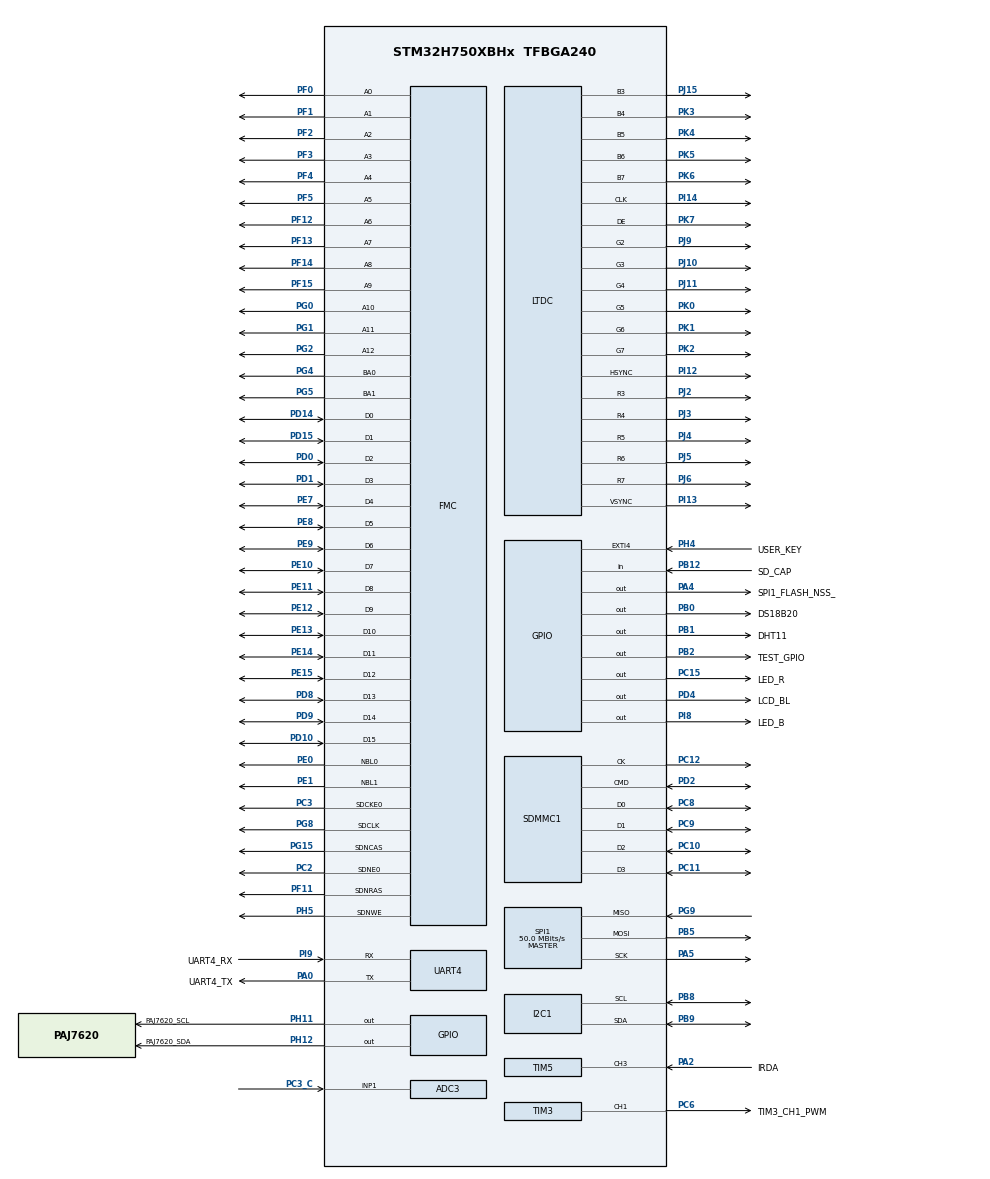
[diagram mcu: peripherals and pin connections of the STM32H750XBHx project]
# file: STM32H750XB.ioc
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ADC3.Channel-0\#ChannelRegularConversion=ADC_CHANNEL_1
ADC3.Channel-1\#ChannelRegularConversion=ADC_CHANNEL_VREFINT
ADC3.Channel-2\#ChannelRegularConversion=ADC_CHANNEL_TEMPSENSOR
ADC3.ClockPrescalerADC3=ADC_CLOCK_ASYNC_DIV2
ADC3.ContinuousConvMode=DISABLE
ADC3.DiscontinuousConvMode=ENABLE
ADC3.NbrOfConversion=3
ADC3.NbrOfConversionFlag=1
ADC3.NbrOfDiscConversion=1
ADC3.OffsetNumber-0\#ChannelRegularConversion=ADC_OFFSET_NONE
ADC3.OffsetNumber-1\#ChannelRegularConversion=ADC_OFFSET_NONE
ADC3.OffsetNumber-2\#ChannelRegularConversion=ADC_OFFSET_NONE
ADC3.OffsetSignedSaturation-0\#ChannelRegularConversion=DISABLE
ADC3.OffsetSignedSaturation-1\#ChannelRegularConversion=DISABLE
ADC3.OffsetSignedSaturation-2\#ChannelRegularConversion=DISABLE
ADC3.Rank-0\#ChannelRegularConversion=1
ADC3.Rank-1\#ChannelRegularConversion=2
ADC3.Rank-2\#ChannelRegularConversion=3
ADC3.SamplingTime-0\#ChannelRegularConversion=ADC_SAMPLETIME_387CYCLES_5
ADC3.SamplingTime-1\#ChannelRegularConversion=ADC_SAMPLETIME_387CYCLES_5
ADC3.SamplingTime-2\#ChannelRegularConversion=ADC_SAMPLETIME_387CYCLES_5
CORTEX_M7.BaseAddress-Cortex_Memory_Protection_Unit_Region0_Settings=0xc0000000
CORTEX_M7.CPU_DCache=Enabled
CORTEX_M7.CPU_ICache=Enabled
CORTEX_M7.Enable-Cortex_Memory_Protection_Unit_Region0_Settings=MPU_REGION_ENABLE
CORTEX_M7.IsBufferable-Cortex_Memory_Protection_Unit_Region0_Settings=MPU_ACCESS_BUFFERABLE
CORTEX_M7.IsCacheable-Cortex_Memory_Protection_Unit_Region0_Settings=MPU_ACCESS_CACHEABLE
CORTEX_M7.MPU_Control=MPU_PRIVILEGED_DEFAULT
CORTEX_M7.Size-Cortex_Memory_Protection_Unit_Region0_Settings=MPU_REGION_SIZE_32MB
CORTEX_M7.default_mode_Activation=0
DMA2D.ColorMode=DMA2D_OUTPUT_RGB888
Dma.Request0=UART4_RX
Dma.Request1=UART4_TX
Dma.UART4_RX.0.Direction=DMA_PERIPH_TO_MEMORY
Dma.UART4_RX.0.EventEnable=DISABLE
Dma.UART4_RX.0.FIFOMode=DMA_FIFOMODE_DISABLE
Dma.UART4_RX.0.Instance=DMA1_Stream2
Dma.UART4_RX.0.MemDataAlignment=DMA_MDATAALIGN_BYTE
Dma.UART4_RX.0.MemInc=DMA_MINC_ENABLE
Dma.UART4_RX.0.Mode=DMA_NORMAL
Dma.UART4_RX.0.PeriphDataAlignment=DMA_PDATAALIGN_BYTE
Dma.UART4_RX.0.PeriphInc=DMA_PINC_DISABLE
Dma.UART4_RX.0.Polarity=HAL_DMAMUX_REQ_GEN_RISING
Dma.UART4_RX.0.Priority=DMA_PRIORITY_MEDIUM
Dma.UART4_RX.0.RequestNumber=1
Dma.UART4_RX.0.SignalID=NONE
Dma.UART4_RX.0.SyncEnable=DISABLE
Dma.UART4_RX.0.SyncPolarity=HAL_DMAMUX_SYNC_NO_EVENT
Dma.UART4_RX.0.SyncRequestNumber=1
Dma.UART4_RX.0.SyncSignalID=NONE
Dma.UART4_TX.1.Direction=DMA_MEMORY_TO_PERIPH
Dma.UART4_TX.1.EventEnable=DISABLE
Dma.UART4_TX.1.FIFOMode=DMA_FIFOMODE_DISABLE
Dma.UART4_TX.1.Instance=DMA1_Stream4
Dma.UART4_TX.1.MemDataAlignment=DMA_MDATAALIGN_BYTE
Dma.UART4_TX.1.MemInc=DMA_MINC_ENABLE
Dma.UART4_TX.1.Mode=DMA_CIRCULAR
Dma.UART4_TX.1.PeriphDataAlignment=DMA_PDATAALIGN_BYTE
Dma.UART4_TX.1.PeriphInc=DMA_PINC_DISABLE
Dma.UART4_TX.1.Polarity=HAL_DMAMUX_REQ_GEN_RISING
Dma.UART4_TX.1.Priority=DMA_PRIORITY_MEDIUM
Dma.UART4_TX.1.RequestNumber=1
Dma.UART4_TX.1.SignalID=NONE
Dma.UART4_TX.1.SyncEnable=DISABLE
Dma.UART4_TX.1.SyncPolarity=HAL_DMAMUX_SYNC_NO_EVENT
Dma.UART4_TX.1.SyncRequestNumber=1
Dma.UART4_TX.1.SyncSignalID=NONE
FATFS.BSP.number=1
FATFS._CODE_PAGE=437
FATFS._USE_LFN=3
FATFS0.BSP.STBoard=false
FATFS0.BSP.api=Unknown
FATFS0.BSP.instance=PB12
FATFS0.BSP.ip=GPIO
FATFS0.BSP.mode=Input
FATFS0.BSP.name=Detect_SDIO
FATFS0.BSP.solution=PB12
FMC.CASLatency1=FMC_SDRAM_CAS_LATENCY_2
FMC.ColumnBitsNumber1=FMC_SDRAM_COLUMN_BITS_NUM_9
FMC.ExitSelfRefreshDelay1=8
FMC.LoadToActiveDelay1=2
FMC.RCDDelay1=2
FMC.RPDelay1=2
FMC.RPDelay2=2
FMC.ReadBurst1=FMC_SDRAM_RBURST_ENABLE
FMC.ReadBurst2=FMC_SDRAM_RBURST_ENABLE
FMC.RowCycleDelay1=6
FMC.RowCycleDelay2=6
FMC.SDClockPeriod1=FMC_SDRAM_CLOCK_PERIOD_2
FMC.SelfRefreshTime1=6
I2C1.Timing=0x00606092
LTDC.ActiveW=800
LTDC.Alpha0_L0=100
LTDC.Alpha0_L1=100
LTDC.Alpha_L0=100
LTDC.Alpha_L1=100
LTDC.FBStartAdress_L0=0xC0000000
LTDC.FBStartAdress_L1=0xC0200000
LTDC.HBP=46
LTDC.HFP=190
LTDC.HSync=2
LTDC.ImageHeight_L0=480
LTDC.ImageHeight_L1=480
LTDC.ImageWidth_L0=800
LTDC.Layers=0
LTDC.PixelFormat_L0=LTDC_PIXEL_FORMAT_RGB565
LTDC.VBP=23
LTDC.VFP=22
LTDC.VSync=2
LTDC.WindowX1_L0=800
LTDC.WindowX1_L1=800
LTDC.WindowY1_L0=480
LTDC.WindowY1_L1=480
Mcu.Family=STM32H7
Mcu.Name=STM32H750XBHx
Mcu.Package=TFBGA240
NVIC.DMA1_Stream2_IRQn=true\:13\:0\:true\:false\:true\:false\:true\:true
NVIC.DMA1_Stream4_IRQn=true\:13\:0\:true\:false\:true\:false\:true\:true
NVIC.DMA2D_IRQn=true\:0\:0\:false\:false\:true\:true\:true\:true
NVIC.EXTI4_IRQn=true\:13\:0\:true\:false\:true\:true\:true\:true
NVIC.FMC_IRQn=true\:0\:0\:false\:false\:true\:true\:true\:true
NVIC.LTDC_ER_IRQn=true\:0\:0\:false\:false\:true\:true\:true\:true
NVIC.LTDC_IRQn=true\:12\:0\:true\:false\:true\:true\:true\:true
NVIC.PriorityGroup=NVIC_PRIORITYGROUP_4
NVIC.TIM5_IRQn=true\:12\:0\:true\:false\:true\:true\:true\:true
NVIC.UART4_IRQn=true\:13\:0\:true\:false\:true\:true\:true\:true
PA0.GPIO_Label=UART4_TX
PA0.Mode=Asynchronous
PA0.Signal=UART4_TX
PA2.GPIO_Label=IRDA
PA2.GPIO_PuPd=GPIO_PULLUP
PA2.GPIO_Speed=GPIO_SPEED_FREQ_MEDIUM
PA2.Signal=S_TIM5_CH3
PA4.GPIO_Label=SPI1_FLASH_NSS_
PA4.GPIO_PuPd=GPIO_PULLDOWN
PA4.GPIO_Speed=GPIO_SPEED_FREQ_VERY_HIGH
PA4.Signal=GPIO_Output
PA5.GPIO_Speed=GPIO_SPEED_FREQ_VERY_HIGH
PA5.Mode=Full_Duplex_Master
PA5.Signal=SPI1_SCK
PB0.GPIO_Label=DS18B20
PB0.PinState=GPIO_PIN_SET
PB0.Signal=GPIO_Output
PB1.GPIO_Label=DHT11
PB1.Signal=GPIO_Output
PB12.GPIO_Label=SD_CAP
PB12.GPIO_PuPd=GPIO_PULLDOWN
PB12.Signal=GPIO_Input
PB2.GPIO_Label=TEST_GPIO
PB2.GPIO_Speed=GPIO_SPEED_FREQ_VERY_HIGH
PB2.Signal=GPIO_Output
PB5.GPIO_Speed=GPIO_SPEED_FREQ_VERY_HIGH
PB5.Mode=Full_Duplex_Master
PB5.Signal=SPI1_MOSI
PB8.Mode=I2C
PB8.Signal=I2C1_SCL
PB9.Mode=I2C
PB9.Signal=I2C1_SDA
PC10.Mode=SD_4_bits_Wide_bus
PC10.Signal=SDMMC1_D2
PC11.Mode=SD_4_bits_Wide_bus
PC11.Signal=SDMMC1_D3
PC12.Mode=SD_4_bits_Wide_bus
PC12.Signal=SDMMC1_CK
PC15-OSC32_OUT\ (OSC32_OUT).GPIO_Label=LED_R
PC15-OSC32_OUT\ (OSC32_OUT).PinState=GPIO_PIN_SET
PC15-OSC32_OUT\ (OSC32_OUT).Signal=GPIO_Output
PC2.GPIO_PuPd=GPIO_NOPULL
PC2.Mode=SdramChipSelect1_1
PC2.Signal=FMC_SDNE0
PC3.Mode=SdramChipSelect1_1
PC3.Signal=FMC_SDCKE0
PC3_C.Mode=IN1-Single-Ended
PC3_C.Signal=ADC3_INP1
PC6.GPIO_Label=TIM3_CH1_PWM
PC6.GPIO_Speed=GPIO_SPEED_FREQ_HIGH
PC6.Signal=S_TIM3_CH1
PC8.Mode=SD_4_bits_Wide_bus
PC8.Signal=SDMMC1_D0
PC9.Mode=SD_4_bits_Wide_bus
PC9.Signal=SDMMC1_D1
PD0.Signal=FMC_D2_DA2
PD1.Signal=FMC_D3_DA3
PD10.Signal=FMC_D15_DA15
PD14.Signal=FMC_D0_DA0
PD15.Signal=FMC_D1_DA1
PD2.Mode=SD_4_bits_Wide_bus
PD2.Signal=SDMMC1_CMD
PD4.GPIO_Label=LCD_BL
PD4.GPIO_Speed=GPIO_SPEED_FREQ_VERY_HIGH
PD4.PinState=GPIO_PIN_SET
PD4.Signal=GPIO_Output
PD8.Signal=FMC_D13_DA13
PD9.Signal=FMC_D14_DA14
PE0.Signal=FMC_NBL0
PE1.Signal=FMC_NBL1
PE10.Signal=FMC_D7_DA7
PE11.Signal=FMC_D8_DA8
PE12.Signal=FMC_D9_DA9
PE13.Signal=FMC_D10_DA10
PE14.Signal=FMC_D11_DA11
PE15.Signal=FMC_D12_DA12
PE7.Signal=FMC_D4_DA4
PE8.Signal=FMC_D5_DA5
PE9.Signal=FMC_D6_DA6
PF0.Signal=FMC_A0
PF1.Signal=FMC_A1
PF11.Signal=FMC_SDNRAS
PF12.Signal=FMC_A6
PF13.Signal=FMC_A7
PF14.Signal=FMC_A8
PF15.Signal=FMC_A9
PF2.Signal=FMC_A2
PF3.Signal=FMC_A3
PF4.Signal=FMC_A4
PF5.Signal=FMC_A5
PG0.Signal=FMC_A10
PG1.Signal=FMC_A11
PG15.Signal=FMC_SDNCAS
PG2.Signal=FMC_A12
PG4.Signal=FMC_A14_BA0
PG5.Signal=FMC_A15_BA1
PG8.Signal=FMC_SDCLK
PG9.GPIO_Speed=GPIO_SPEED_FREQ_VERY_HIGH
PG9.Mode=Full_Duplex_Master
PG9.Signal=SPI1_MISO
PH0-OSC_IN\ (PH0).Mode=HSE-External-Oscillator
PH0-OSC_IN\ (PH0).Signal=RCC_OSC_IN
PH1-OSC_OUT\ (PH1).Mode=HSE-External-Oscillator
PH1-OSC_OUT\ (PH1).Signal=RCC_OSC_OUT
PH11.GPIO_Label=PAJ7620_SCL
PH11.GPIO_PuPd=GPIO_PULLUP
PH11.Signal=GPIO_Output
PH12.GPIO_Label=PAJ7620_SDA
PH12.GPIO_PuPd=GPIO_PULLUP
PH12.Signal=GPIO_Output
PH4.GPIO_Label=USER_KEY
PH4.GPIO_PuPd=GPIO_PULLUP
PH4.Signal=GPXTI4
PH5.GPIO_PuPd=GPIO_PULLDOWN
PH5.Signal=FMC_SDNWE
PI12.GPIO_Speed=GPIO_SPEED_FREQ_VERY_HIGH
PI12.Mode=RGB565
PI12.Signal=LTDC_HSYNC
PI13.GPIO_Speed=GPIO_SPEED_FREQ_VERY_HIGH
PI13.Mode=RGB565
PI13.Signal=LTDC_VSYNC
PI14.GPIO_Speed=GPIO_SPEED_FREQ_VERY_HIGH
PI14.Mode=RGB565
PI14.Signal=LTDC_CLK
PI15.GPIO_Speed=GPIO_SPEED_FREQ_VERY_HIGH
PI15.Signal=LTDC_R0
PI8.GPIO_Label=LED_B
PI8.PinState=GPIO_PIN_SET
PI8.Signal=GPIO_Output
PI9.GPIO_Label=UART4_RX
PI9.Mode=Asynchronous
PI9.Signal=UART4_RX
PJ1.GPIO_Speed=GPIO_SPEED_FREQ_VERY_HIGH
PJ1.Signal=LTDC_R2
PJ10.GPIO_Speed=GPIO_SPEED_FREQ_VERY_HIGH
PJ10.Mode=RGB565
PJ10.Signal=LTDC_G3
PJ11.GPIO_Speed=GPIO_SPEED_FREQ_VERY_HIGH
PJ11.Mode=RGB565
PJ11.Signal=LTDC_G4
PJ12.GPIO_Speed=GPIO_SPEED_FREQ_VERY_HIGH
PJ12.Signal=LTDC_B0
PJ13.GPIO_Speed=GPIO_SPEED_FREQ_VERY_HIGH
PJ13.Signal=LTDC_B1
PJ14.GPIO_Speed=GPIO_SPEED_FREQ_VERY_HIGH
PJ14.Signal=LTDC_B2
PJ15.GPIO_Speed=GPIO_SPEED_FREQ_VERY_HIGH
PJ15.Mode=RGB565
PJ15.Signal=LTDC_B3
PJ2.GPIO_Speed=GPIO_SPEED_FREQ_VERY_HIGH
PJ2.Mode=RGB565
PJ2.Signal=LTDC_R3
PJ3.GPIO_Speed=GPIO_SPEED_FREQ_VERY_HIGH
PJ3.Mode=RGB565
PJ3.Signal=LTDC_R4
PJ4.GPIO_Speed=GPIO_SPEED_FREQ_VERY_HIGH
PJ4.Mode=RGB565
PJ4.Signal=LTDC_R5
PJ5.GPIO_Speed=GPIO_SPEED_FREQ_VERY_HIGH
PJ5.Mode=RGB565
PJ5.Signal=LTDC_R6
PJ6.GPIO_Speed=GPIO_SPEED_FREQ_VERY_HIGH
PJ6.Mode=RGB565
PJ6.Signal=LTDC_R7
PJ7.GPIO_Speed=GPIO_SPEED_FREQ_VERY_HIGH
PJ7.Signal=LTDC_G0
PJ8.GPIO_Speed=GPIO_SPEED_FREQ_VERY_HIGH
PJ8.Signal=LTDC_G1
PJ9.GPIO_Speed=GPIO_SPEED_FREQ_VERY_HIGH
PJ9.Mode=RGB565
PJ9.Signal=LTDC_G2
PK0.GPIO_Speed=GPIO_SPEED_FREQ_VERY_HIGH
PK0.Mode=RGB565
PK0.Signal=LTDC_G5
PK1.GPIO_Speed=GPIO_SPEED_FREQ_VERY_HIGH
PK1.Mode=RGB565
PK1.Signal=LTDC_G6
PK2.GPIO_Speed=GPIO_SPEED_FREQ_VERY_HIGH
PK2.Mode=RGB565
PK2.Signal=LTDC_G7
PK3.GPIO_Speed=GPIO_SPEED_FREQ_VERY_HIGH
PK3.Mode=RGB565
PK3.Signal=LTDC_B4
PK4.GPIO_Speed=GPIO_SPEED_FREQ_VERY_HIGH
PK4.Mode=RGB565
PK4.Signal=LTDC_B5
PK5.GPIO_Speed=GPIO_SPEED_FREQ_VERY_HIGH
PK5.Mode=RGB565
PK5.Signal=LTDC_B6
PK6.GPIO_Speed=GPIO_SPEED_FREQ_VERY_HIGH
PK6.Mode=RGB565
PK6.Signal=LTDC_B7
PK7.GPIO_Speed=GPIO_SPEED_FREQ_VERY_HIGH
PK7.Mode=RGB565
PK7.Signal=LTDC_DE
ProjectManager.HeapSize=0x200
ProjectManager.StackSize=0x1000
ProjectManager.TargetToolchain=MDK-ARM V5.27
RCC.ADCFreq_Value=50000000
RCC.APB1Freq_Value=120000000
RCC.APB2Freq_Value=120000000
RCC.APB3Freq_Value=120000000
RCC.APB4Freq_Value=120000000
RCC.CortexFreq_Value=480000000
RCC.D1PPRE=RCC_APB3_DIV2
RCC.D2PPRE1=RCC_APB1_DIV2
RCC.D2PPRE2=RCC_APB2_DIV2
RCC.D3PPRE=RCC_APB4_DIV2
RCC.DIVM1=5
RCC.DIVM2=25
RCC.DIVM3=5
RCC.DIVN1=192
RCC.DIVN2=200
RCC.DIVN3=80
RCC.DIVP2=4
RCC.DIVP3=4
RCC.DIVQ1=5
RCC.DIVR2=1
RCC.DIVR3=16
RCC.FMCCLockSelection=RCC_FMCCLKSOURCE_PLL2
RCC.HCLKFreq_Value=240000000
RCC.HPRE=RCC_HCLK_DIV2
RCC.I2C123CLockSelection=RCC_I2C123CLKSOURCE_PLL3
RCC.PLLFRACN=0
RCC.PLLSourceVirtual=RCC_PLLSOURCE_HSE
RCC.PWR_Regulator_Voltage_Scale=PWR_REGULATOR_VOLTAGE_SCALE0
RCC.ProductRev=revV
RCC.SPI123CLockSelection=RCC_SPI123CLKSOURCE_PLL3
RCC.SYSCLKFreq_VALUE=480000000
RCC.SYSCLKSource=RCC_SYSCLKSOURCE_PLLCLK
RCC.USART234578CLockSelection=RCC_USART234578CLKSOURCE_PLL2
RCC.USBFreq_Value=192000000
SDMMC1.ClockDiv=6
SH.FMC_A0.0=FMC_A0,13b-sda1
SH.FMC_A1.0=FMC_A1,13b-sda1
SH.FMC_A10.0=FMC_A10,13b-sda1
SH.FMC_A11.0=FMC_A11,13b-sda1
SH.FMC_A12.0=FMC_A12,13b-sda1
SH.FMC_A14_BA0.0=FMC_BA0,FourSdramBanks1
SH.FMC_A15_BA1.0=FMC_BA1,FourSdramBanks1
SH.FMC_A2.0=FMC_A2,13b-sda1
SH.FMC_A3.0=FMC_A3,13b-sda1
SH.FMC_A4.0=FMC_A4,13b-sda1
SH.FMC_A5.0=FMC_A5,13b-sda1
SH.FMC_A6.0=FMC_A6,13b-sda1
SH.FMC_A7.0=FMC_A7,13b-sda1
SH.FMC_A8.0=FMC_A8,13b-sda1
SH.FMC_A9.0=FMC_A9,13b-sda1
SH.FMC_D0_DA0.0=FMC_D0,sd-16b-d1
SH.FMC_D10_DA10.0=FMC_D10,sd-16b-d1
SH.FMC_D11_DA11.0=FMC_D11,sd-16b-d1
SH.FMC_D12_DA12.0=FMC_D12,sd-16b-d1
SH.FMC_D13_DA13.0=FMC_D13,sd-16b-d1
SH.FMC_D14_DA14.0=FMC_D14,sd-16b-d1
SH.FMC_D15_DA15.0=FMC_D15,sd-16b-d1
SH.FMC_D1_DA1.0=FMC_D1,sd-16b-d1
SH.FMC_D2_DA2.0=FMC_D2,sd-16b-d1
SH.FMC_D3_DA3.0=FMC_D3,sd-16b-d1
SH.FMC_D4_DA4.0=FMC_D4,sd-16b-d1
SH.FMC_D5_DA5.0=FMC_D5,sd-16b-d1
SH.FMC_D6_DA6.0=FMC_D6,sd-16b-d1
SH.FMC_D7_DA7.0=FMC_D7,sd-16b-d1
SH.FMC_D8_DA8.0=FMC_D8,sd-16b-d1
SH.FMC_D9_DA9.0=FMC_D9,sd-16b-d1
SH.FMC_NBL0.0=FMC_NBL0,Sd2ByteEnable1
SH.FMC_NBL1.0=FMC_NBL1,Sd2ByteEnable1
SH.FMC_SDCLK.0=FMC_SDCLK,13b-sda1
SH.FMC_SDNCAS.0=FMC_SDNCAS,13b-sda1
SH.FMC_SDNRAS.0=FMC_SDNRAS,13b-sda1
SH.FMC_SDNWE.0=FMC_SDNWE,13b-sda1
SH.S_TIM3_CH1.0=TIM3_CH1,PWM Generation1 CH1
SH.S_TIM5_CH3.0=TIM5_CH3,Input_Capture3_from_TI3
SPI1.CalculateBaudRate=50.0 MBits/s
SPI1.DataSize=SPI_DATASIZE_8BIT
SPI1.Direction=SPI_DIRECTION_2LINES
SPI1.Mode=SPI_MODE_MASTER
SPI1.VirtualType=VM_MASTER
STMicroelectronics.X-CUBE-TOUCHGFX.4.22.0.ApplicationCcGraphicsJjApplication=TouchGFXOoGenerator
STMicroelectronics.X-CUBE-TOUCHGFX.4.22.0.tgfx_address1=0xc0000000
STMicroelectronics.X-CUBE-TOUCHGFX.4.22.0.tgfx_display_interface=disp_ltdc
STMicroelectronics.X-CUBE-TOUCHGFX.4.22.0.tgfx_hardware_accelerator=dma_2d
STMicroelectronics.X-CUBE-TOUCHGFX.4.22.0.tgfx_location=By Address
STMicroelectronics.X-CUBE-TOUCHGFX.4.22.0.tgfx_oswrapper=NoOS
STMicroelectronics.X-CUBE-TOUCHGFX.4.22.0.tgfx_vsync=vsync_ltdc
STMicroelectronics.X-CUBE-TOUCHGFX.4.22.0_IsPackSelfContextualization=true
TIM3.AutoReloadPreload=TIM_AUTORELOAD_PRELOAD_ENABLE
TIM3.Channel-PWM\ Generation1\ CH1=TIM_CHANNEL_1
TIM3.Prescaler=23
TIM3.Pulse-PWM\ Generation1\ CH1=3000
TIM5.AutoReloadPreload=TIM_AUTORELOAD_PRELOAD_ENABLE
TIM5.Channel-Input_Capture3_from_TI3=TIM_CHANNEL_3
TIM5.ICPolarity_CH3=TIM_INPUTCHANNELPOLARITY_FALLING
TIM5.Period=65535
TIM5.Prescaler=2399
TIM6.AutoReloadPreload=TIM_AUTORELOAD_PRELOAD_ENABLE
TIM6.Period=19
TIM6.Prescaler=119
UART4.OverSampling=UART_OVERSAMPLING_16
VP_ADC3_TempSens_Input.Mode=IN-TempSens
VP_ADC3_Vref_Input.Mode=IN-Vrefint
VP_CRC_VS_CRC.Mode=CRC_Activate
VP_DMA2D_VS_DMA2D.Mode=DMA2D_Activate
VP_FATFS_VS_SDIO.Mode=SDIO
VP_STMicroelectronics.X-CUBE-TOUCHGFX_VS_GraphicsJjApplication_4.22.0.Mode=GraphicsJjApplication
VP_TIM5_VS_ClockSourceINT.Mode=Internal
VP_TIM6_VS_ClockSourceINT.Mode=Enable_Timer
board=custom

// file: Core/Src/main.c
/* USER CODE BEGIN Header */
/**
  ******************************************************************************
  * @file           : main.c
  * @brief          : Main program body
  ******************************************************************************
  * @attention
  *
  * Copyright (c) 2024 STMicroelectronics.
  * All rights reserved.
  *
  * This software is licensed under terms that can be found in the LICENSE file
  * in the root directory of this software component.
  * If no LICENSE file comes with this software, it is provided AS-IS.
  *
  ******************************************************************************
  */
/* USER CODE END Header */
#include "main.h"
#include "adc.h"
#include "crc.h"
#include "dma.h"
#include "dma2d.h"
#include "fatfs.h"
#include "i2c.h"
#include "ltdc.h"
#include "sdmmc.h"
#include "spi.h"
#include "tim.h"
#include "usart.h"
#include "gpio.h"
#include "fmc.h"
#include "app_touchgfx.h"

/* USER CODE BEGIN Includes */
#include "creat_task.h"
#include "stdio.h"
#include "bsp_sdram.h"
/* USER CODE END Includes */

void SystemClock_Config(void);
void PeriphCommonClock_Config(void);
static void MPU_Config(void);

int main(void)
{
  /* USER CODE BEGIN 1 */
	SCB->VTOR = 0X90000000;
//
  __enable_irq();

  /* USER CODE END 1 */

  /* MPU Configuration--------------------------------------------------------*/
//  MPU_Config();

  /* Enable I-Cache---------------------------------------------------------*/
  SCB_EnableICache();

  /* Enable D-Cache---------------------------------------------------------*/
  SCB_EnableDCache();

  /* MCU Configuration--------------------------------------------------------*/

  /* Reset of all peripherals, Initializes the Flash interface and the Systick. */
  HAL_Init();

  /* Configure the system clock */
  SystemClock_Config();

/* Configure the peripherals common clocks */
  PeriphCommonClock_Config();

  /* Initialize all configured peripherals */
  MX_GPIO_Init();
  MX_DMA_Init();
  MX_UART4_Init();
  MX_ADC3_Init();
  MX_TIM3_Init();
  MX_TIM5_Init();
  MX_TIM6_Init();
  MX_I2C1_Init();
  MX_FMC_Init();
  MX_DMA2D_Init();
  MX_LTDC_Init();
  MX_SDMMC1_SD_Init();
  MX_FATFS_Init();
  MX_SPI1_Init();
  MX_CRC_Init();
  MX_TouchGFX_Init();
  /* USER CODE BEGIN 2 */
  SDRAM_InitSequence();

//	FreeRTOS_Start();

  /* USER CODE END 2 */

  /* Infinite loop */
  while (1)
  {

  MX_TouchGFX_Process();
  }
}

void SystemClock_Config(void)
{
  RCC_OscInitTypeDef RCC_OscInitStruct = {0};
  RCC_ClkInitTypeDef RCC_ClkInitStruct = {0};

  /** Supply configuration update enable
  */
  HAL_PWREx_ConfigSupply(PWR_LDO_SUPPLY);

  /** Configure the main internal regulator output voltage
  */
  __HAL_PWR_VOLTAGESCALING_CONFIG(PWR_REGULATOR_VOLTAGE_SCALE1);

  while(!__HAL_PWR_GET_FLAG(PWR_FLAG_VOSRDY)) {}

  __HAL_RCC_SYSCFG_CLK_ENABLE();
  __HAL_PWR_VOLTAGESCALING_CONFIG(PWR_REGULATOR_VOLTAGE_SCALE0);

  while(!__HAL_PWR_GET_FLAG(PWR_FLAG_VOSRDY)) {}

  /** Initializes the RCC Oscillators according to the specified parameters
  * in the RCC_OscInitTypeDef structure.
  */
  RCC_OscInitStruct.OscillatorType = RCC_OSCILLATORTYPE_HSE;
  RCC_OscInitStruct.HSEState = RCC_HSE_ON;
  RCC_OscInitStruct.PLL.PLLState = RCC_PLL_ON;
  RCC_OscInitStruct.PLL.PLLSource = RCC_PLLSOURCE_HSE;
  RCC_OscInitStruct.PLL.PLLM = 5;
  RCC_OscInitStruct.PLL.PLLN = 192;
  RCC_OscInitStruct.PLL.PLLP = 2;
  RCC_OscInitStruct.PLL.PLLQ = 5;
  RCC_OscInitStruct.PLL.PLLR = 2;
  RCC_OscInitStruct.PLL.PLLRGE = RCC_PLL1VCIRANGE_2;
  RCC_OscInitStruct.PLL.PLLVCOSEL = RCC_PLL1VCOWIDE;
  RCC_OscInitStruct.PLL.PLLFRACN = 0;
  if (HAL_RCC_OscConfig(&RCC_OscInitStruct) != HAL_OK)
  {
    Error_Handler();
  }

  /** Initializes the CPU, AHB and APB buses clocks
  */
  RCC_ClkInitStruct.ClockType = RCC_CLOCKTYPE_HCLK|RCC_CLOCKTYPE_SYSCLK
                              |RCC_CLOCKTYPE_PCLK1|RCC_CLOCKTYPE_PCLK2
                              |RCC_CLOCKTYPE_D3PCLK1|RCC_CLOCKTYPE_D1PCLK1;
  RCC_ClkInitStruct.SYSCLKSource = RCC_SYSCLKSOURCE_PLLCLK;
  RCC_ClkInitStruct.SYSCLKDivider = RCC_SYSCLK_DIV1;
  RCC_ClkInitStruct.AHBCLKDivider = RCC_HCLK_DIV2;
  RCC_ClkInitStruct.APB3CLKDivider = RCC_APB3_DIV2;
  RCC_ClkInitStruct.APB1CLKDivider = RCC_APB1_DIV2;
  RCC_ClkInitStruct.APB2CLKDivider = RCC_APB2_DIV2;
  RCC_ClkInitStruct.APB4CLKDivider = RCC_APB4_DIV2;

  if (HAL_RCC_ClockConfig(&RCC_ClkInitStruct, FLASH_LATENCY_4) != HAL_OK)
  {
    Error_Handler();
  }
}

void PeriphCommonClock_Config(void)
{
  RCC_PeriphCLKInitTypeDef PeriphClkInitStruct = {0};

  /** Initializes the peripherals clock
  */
  PeriphClkInitStruct.PeriphClockSelection = RCC_PERIPHCLK_FMC|RCC_PERIPHCLK_ADC
                              |RCC_PERIPHCLK_I2C1|RCC_PERIPHCLK_SPI1
                              |RCC_PERIPHCLK_UART4|RCC_PERIPHCLK_LTDC;
  PeriphClkInitStruct.PLL2.PLL2M = 25;
  PeriphClkInitStruct.PLL2.PLL2N = 200;
  PeriphClkInitStruct.PLL2.PLL2P = 4;
  PeriphClkInitStruct.PLL2.PLL2Q = 2;
  PeriphClkInitStruct.PLL2.PLL2R = 1;
  PeriphClkInitStruct.PLL2.PLL2RGE = RCC_PLL2VCIRANGE_0;
  PeriphClkInitStruct.PLL2.PLL2VCOSEL = RCC_PLL2VCOWIDE;
  PeriphClkInitStruct.PLL2.PLL2FRACN = 0;
  PeriphClkInitStruct.PLL3.PLL3M = 5;
  PeriphClkInitStruct.PLL3.PLL3N = 80;
  PeriphClkInitStruct.PLL3.PLL3P = 4;
  PeriphClkInitStruct.PLL3.PLL3Q = 2;
  PeriphClkInitStruct.PLL3.PLL3R = 16;
  PeriphClkInitStruct.PLL3.PLL3RGE = RCC_PLL3VCIRANGE_2;
  PeriphClkInitStruct.PLL3.PLL3VCOSEL = RCC_PLL3VCOWIDE;
  PeriphClkInitStruct.PLL3.PLL3FRACN = 0;
  PeriphClkInitStruct.FmcClockSelection = RCC_FMCCLKSOURCE_PLL2;
  PeriphClkInitStruct.Spi123ClockSelection = RCC_SPI123CLKSOURCE_PLL3;
  PeriphClkInitStruct.Usart234578ClockSelection = RCC_USART234578CLKSOURCE_PLL2;
  PeriphClkInitStruct.I2c123ClockSelection = RCC_I2C123CLKSOURCE_PLL3;
  PeriphClkInitStruct.AdcClockSelection = RCC_ADCCLKSOURCE_PLL2;
  if (HAL_RCCEx_PeriphCLKConfig(&PeriphClkInitStruct) != HAL_OK)
  {
    Error_Handler();
  }
}

/* MPU Configuration */

void MPU_Config(void)
{
  MPU_Region_InitTypeDef MPU_InitStruct = {0};

  /* Disables the MPU */
  HAL_MPU_Disable();

  /** Initializes and configures the Region and the memory to be protected
  */
  MPU_InitStruct.Enable = MPU_REGION_ENABLE;
  MPU_InitStruct.Number = MPU_REGION_NUMBER0;
  MPU_InitStruct.BaseAddress = 0xc0000000;
  MPU_InitStruct.Size = MPU_REGION_SIZE_32MB;
  MPU_InitStruct.SubRegionDisable = 0x0;
  MPU_InitStruct.TypeExtField = MPU_TEX_LEVEL0;
  MPU_InitStruct.AccessPermission = MPU_REGION_NO_ACCESS;
  MPU_InitStruct.DisableExec = MPU_INSTRUCTION_ACCESS_ENABLE;
  MPU_InitStruct.IsShareable = MPU_ACCESS_NOT_SHAREABLE;
  MPU_InitStruct.IsCacheable = MPU_ACCESS_CACHEABLE;
  MPU_InitStruct.IsBufferable = MPU_ACCESS_BUFFERABLE;

  HAL_MPU_ConfigRegion(&MPU_InitStruct);
  /* Enables the MPU */
  HAL_MPU_Enable(MPU_PRIVILEGED_DEFAULT);

}

void Error_Handler(void)
{
  __disable_irq();
  while (1)
  {
  }
}
